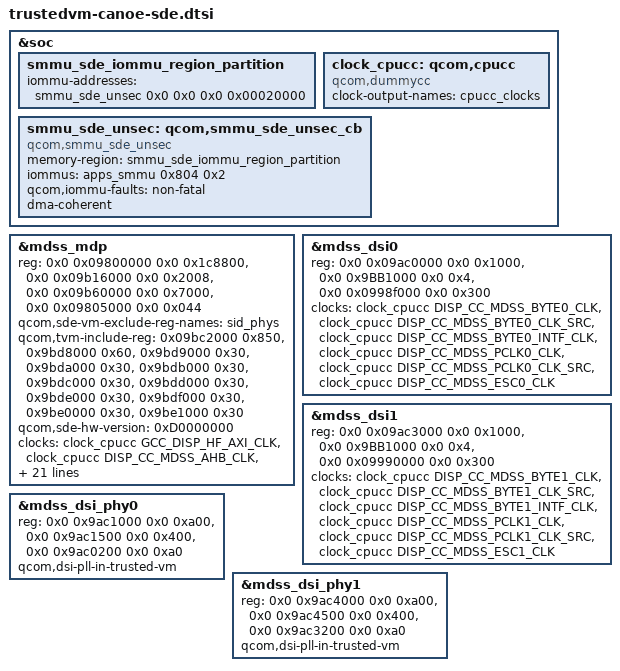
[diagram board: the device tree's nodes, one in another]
// SPDX-License-Identifier: BSD-3-Clause
/*
 * Copyright (c) Qualcomm Technologies, Inc. and/or its subsidiaries.
 */

#include <dt-bindings/clock/qcom,dispcc-canoe.h>
#include <dt-bindings/clock/qcom,gcc-canoe.h>
#include "canoe-sde-common.dtsi"
#include "trustedvm-canoe-avf-required-subnodes.dtsi"

&soc {
	smmu_sde_iommu_region_partition: smmu_sde_iommu_region_partition {
		iommu-addresses = <&smmu_sde_unsec 0x0 0x0 0x0 0x00020000>;
	};

	/* dummy display clock provider */
	clock_cpucc: qcom,cpucc {
		compatible = "qcom,dummycc";
		clock-output-names = "cpucc_clocks";
		#clock-cells = <1>;
	};

	smmu_sde_unsec: qcom,smmu_sde_unsec_cb {
		compatible = "qcom,smmu_sde_unsec";
		memory-region = <&smmu_sde_iommu_region_partition>;
		iommus = <&apps_smmu 0x804 0x2>;
		qcom,iommu-faults = "non-fatal";
		dma-coherent;
	};
};

&mdss_mdp {
	reg = <0x0 0x09800000 0x0 0x1c8800>,
		<0x0 0x09b16000 0x0 0x2008>,
		<0x0 0x09b60000 0x0 0x7000>,
		<0x0 0x09805000 0x0 0x044>;
	reg-names = "mdp_phys",
		"vbif_phys",
		"regdma_phys",
		"sid_phys";

	qcom,sde-vm-exclude-reg-names = "sid_phys";

	qcom,tvm-include-reg =  <0x09bc2000 0x850>,
				<0x9bd8000 0x60>,
				<0x9bd9000 0x30>,
				<0x9bda000 0x30>,
				<0x9bdb000 0x30>,
				<0x9bdc000 0x30>,
				<0x9bdd000 0x30>,
				<0x9bde000 0x30>,
				<0x9bdf000 0x30>,
				<0x9be0000 0x30>,
				<0x9be1000 0x30>;

	qcom,sde-hw-version =<0xD0000000>;

	clocks = <&clock_cpucc GCC_DISP_HF_AXI_CLK>,
		<&clock_cpucc DISP_CC_MDSS_AHB_CLK>,
		<&clock_cpucc DISP_CC_MDSS_MDP_CLK>,
		<&clock_cpucc DISP_CC_MDSS_MDP_CLK_SRC>,
		<&clock_cpucc DISP_CC_MDSS_VSYNC_CLK>,
		<&clock_cpucc DISP_CC_MDSS_MDP_LUT_CLK>,
		<&clock_cpucc DISP_CC_MDSS_MDP_SS_IP_CLK>;

	clock-names = "gcc_bus", "iface_clk", "branch_clk", "core_clk",
		"vsync_clk", "lut_clk", "ssip_clk";
	qcom,sde-trusted-vm-env;

	qcom,sde-sspp-type = "vig", "vig",
			"dma", "dma", "dma", "dma";
	qcom,sde-sspp-off = <0x2c000 0x35000
			0x98000 0xa1000 0xaa000 0xb3000>;
	qcom,sde-sspp-xin-id = <0 4 1 5 9 13>;
	qcom,sde-sspp-excl-rect = <1 1 1 1 1 1>;
	qcom,sde-sspp-smart-dma-priority = <5 6 1 2 3 4>;

	qcom,sde-max-per-pipe-bw-kbps = <4500000 4500000
					4500000 4500000
					4500000 4500000>;

	qcom,sde-max-per-pipe-bw-high-kbps = <7100000 7100000
						7100000 7100000
						7100000 7100000>;
	/* offsets are relative to "mdp_phys + qcom,sde-off */
	qcom,sde-sspp-clk-ctrl =
			<0x4330 0>, <0x6330 0>,
			<0x24330 0>, <0x26330 0>, <0x28330 0>, <0x2a330 0>;
	qcom,sde-sspp-clk-status =
			<0x4334 0>, <0x6334 0>,
			<0x24334 0>, <0x26334 0>, <0x28334 0>, <0x2a334 0>;

};

&mdss_dsi0 {
	reg = <0x0 0x09ac0000 0x0 0x1000>,
		  <0x0 0x9BB1000 0x0 0x4>,
		  <0x0 0x0998f000 0x0 0x300>;
	reg-names = "dsi_ctrl", "disp_cc_base", "mdp_intf_base";

	clocks = <&clock_cpucc DISP_CC_MDSS_BYTE0_CLK>,
		<&clock_cpucc DISP_CC_MDSS_BYTE0_CLK_SRC>,
		<&clock_cpucc DISP_CC_MDSS_BYTE0_INTF_CLK>,
		<&clock_cpucc DISP_CC_MDSS_PCLK0_CLK>,
		<&clock_cpucc DISP_CC_MDSS_PCLK0_CLK_SRC>,
		<&clock_cpucc DISP_CC_MDSS_ESC0_CLK>;
	clock-names = "byte_clk", "byte_clk_rcg", "byte_intf_clk",
			"pixel_clk", "pixel_clk_rcg", "esc_clk";
};

&mdss_dsi1 {
	reg = <0x0 0x09ac3000 0x0 0x1000>,
		<0x0 0x9BB1000 0x0 0x4>,
		<0x0 0x09990000 0x0 0x300>;
	reg-names = "dsi_ctrl", "disp_cc_base", "mdp_intf_base";

	clocks = <&clock_cpucc DISP_CC_MDSS_BYTE1_CLK>,
		<&clock_cpucc DISP_CC_MDSS_BYTE1_CLK_SRC>,
		<&clock_cpucc DISP_CC_MDSS_BYTE1_INTF_CLK>,
		<&clock_cpucc DISP_CC_MDSS_PCLK1_CLK>,
		<&clock_cpucc DISP_CC_MDSS_PCLK1_CLK_SRC>,
		<&clock_cpucc DISP_CC_MDSS_ESC1_CLK>;
	clock-names = "byte_clk", "byte_clk_rcg", "byte_intf_clk",
			"pixel_clk", "pixel_clk_rcg", "esc_clk";
};

&mdss_dsi_phy0 {
	reg = <0x0 0x9ac1000 0x0 0xa00>,
		<0x0 0x9ac1500 0x0 0x400>,
		<0x0 0x9ac0200 0x0 0xa0>;
	reg-names = "dsi_phy", "pll_base", "dyn_refresh_base";

	qcom,dsi-pll-in-trusted-vm;
};

&mdss_dsi_phy1 {
	reg = <0x0 0x9ac4000 0x0 0xa00>,
		<0x0 0x9ac4500 0x0 0x400>,
		<0x0 0x9ac3200 0x0 0xa0>;
	reg-names = "dsi_phy", "pll_base", "dyn_refresh_base";
	qcom,dsi-pll-in-trusted-vm;
};
